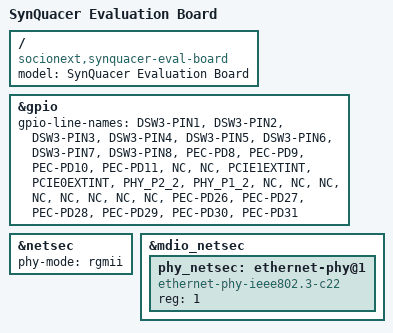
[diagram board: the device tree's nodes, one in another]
/** @file
 * Copyright (c) 2017, Linaro Limited. All rights reserved.
 *
 * SPDX-License-Identifier: BSD-2-Clause-Patent
 */

/dts-v1/;

#include "SynQuacer.dtsi"

/ {
    model = "SynQuacer Evaluation Board";
    compatible = "socionext,synquacer-eval-board", "socionext,synquacer";
};

&gpio {
    gpio-line-names = "DSW3-PIN1",  "DSW3-PIN2",  "DSW3-PIN3",    "DSW3-PIN4",
                      "DSW3-PIN5",  "DSW3-PIN6",  "DSW3-PIN7",    "DSW3-PIN8",
                      "PEC-PD8",    "PEC-PD9",    "PEC-PD10",     "PEC-PD11",
                      "NC",         "NC",         "PCIE1EXTINT",  "PCIE0EXTINT",
                      "PHY_P2_2",   "PHY_P1_2",   "NC",           "NC",
                      "NC",         "NC",         "NC",           "NC",
                      "NC",         "NC",         "PEC-PD26",     "PEC-PD27",
                      "PEC-PD28",   "PEC-PD29",   "PEC-PD30",     "PEC-PD31";
};

&netsec {
    phy-mode = "rgmii";
};

&mdio_netsec {
    phy_netsec: ethernet-phy@1 {
        compatible = "ethernet-phy-ieee802.3-c22";
        reg = <1>;
    };
};
